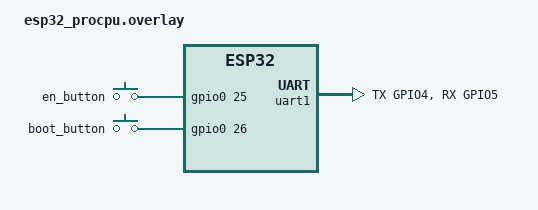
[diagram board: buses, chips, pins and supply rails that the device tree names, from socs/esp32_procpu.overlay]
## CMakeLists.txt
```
# SPDX-License-Identifier: Apache-2.0

cmake_minimum_required(VERSION 3.20.0)

find_package(Zephyr REQUIRED HINTS $ENV{ZEPHYR_BASE})
project(zephyr_flasher)

zephyr_compile_definitions_ifdef(CONFIG_SERIAL_FLASHER_MD5_ENABLED MD5_ENABLED)

zephyr_library_sources(
  ../common/example_common.c
  )

zephyr_library_include_directories(
  ../common
  )

# Needed for example_common
add_compile_definitions(SERIAL_FLASHER_INTERFACE_UART)

# Convert binary files to C source files using bin2array.cmake
include(${CMAKE_SOURCE_DIR}/../common/bin2array.cmake)
create_resources(${CMAKE_SOURCE_DIR}/target-firmware ${CMAKE_BINARY_DIR}/target_firmware_data.c)
set_property(SOURCE ${CMAKE_BINARY_DIR}/target_firmware_data.c PROPERTY GENERATED 1)

target_sources(app PRIVATE
    src/main.c
    ${CMAKE_BINARY_DIR}/target_firmware_data.c
)
```

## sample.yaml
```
sample:
  description: ESP Serial Flasher sample code
  name: zephyr_flasher
tests:
  sample.esp_flasher.zephyr_example:
    platform_allow:
      - esp32_devkitc_wroom
      - esp32_devkitc_wrover
    tags: esp32
```

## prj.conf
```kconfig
# nothing here
CONFIG_CONSOLE=y
CONFIG_CONSOLE_GETCHAR=y
CONFIG_NEWLIB_LIBC=y
```

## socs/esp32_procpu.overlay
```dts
/*
 * Copyright (c) 2024 Espressif Systems (Shanghai) Co., Ltd.
 *
 * SPDX-License-Identifier: Apache-2.0
 */

/ {
	aliases {
		en = &en_button;
		boot = &boot_button;
		uart = &uart1;
	};

	gpio_keys {
		compatible = "gpio-keys";
		en_button: en_button {
			gpios = <&gpio0 25 (GPIO_PULL_UP | GPIO_ACTIVE_HIGH)>;
		};
		boot_button: boot_button {
			gpios = <&gpio0 26 (GPIO_PULL_UP | GPIO_ACTIVE_HIGH)>;
		};
	};
};

&pinctrl {
	uart1_example: uart1_example {
		group1 {
			pinmux = <UART1_TX_GPIO4>;
			input-enable;
		};
		group2 {
			pinmux = <UART1_RX_GPIO5>;
			output-enable;
		};
	};
};

&uart1 {
	status = "okay";
	pinctrl-0 = <&uart1_example>;
	pinctrl-names = "default";
};
```

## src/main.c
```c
/*
 * ESP Flasher Library Example for Zephyr
 * Written in 2022 by KT-Elektronik, Klaucke und Partner GmbH
 * This example code is in the Public Domain (or CC0 licensed, at your option.)
 * Unless required by applicable law or agreed to in writing, this
 * software is distributed on an "AS IS" BASIS, WITHOUT WARRANTIES OR
 * CONDITIONS OF ANY KIND, either express or implied.
 *
 * Copyright (c) 2023 Espressif Systems (Shanghai) Co., Ltd.
 */

#include <zephyr/kernel.h>
#include <zephyr/device.h>
#include <zephyr/devicetree.h>
#include <zephyr/drivers/gpio.h>
#include <zephyr/drivers/uart.h>
#include <zephyr/sys/util.h>

#include <stdio.h>
#include <string.h>
#include <zephyr_port.h>
#include <esp_loader.h>
#include "example_common.h"

// Embedded binary files using bin2array.cmake
extern const uint8_t bootloader_bin[];
extern const uint32_t bootloader_bin_size;
extern const uint8_t bootloader_bin_md5[];
extern const uint8_t partition_table_bin[];
extern const uint32_t partition_table_bin_size;
extern const uint8_t partition_table_bin_md5[];
extern const uint8_t app_bin[];
extern const uint32_t app_bin_size;
extern const uint8_t app_bin_md5[];

#define HIGHER_BAUDRATE 230400
#define DEFAULT_BAUDRATE 115200

/* Get UART DTS entry used as flash interface */
static const struct device *esp_uart_dev = DEVICE_DT_GET(DT_ALIAS(uart));
/* Get GPIO pin connected to the ESP's enable pin. */
static const struct gpio_dt_spec esp_enable_spec = GPIO_DT_SPEC_GET(DT_ALIAS(en), gpios);
/* Get GPIO pin  connected to the ESP's boot pin. */
static const struct gpio_dt_spec esp_boot_spec = GPIO_DT_SPEC_GET(DT_ALIAS(boot), gpios);

int main(void)
{

    const loader_zephyr_config_t config = {
        .uart_dev = esp_uart_dev,
        .enable_spec = esp_enable_spec,
        .boot_spec = esp_boot_spec
    };

    printk("Running ESP Flasher from Zephyr\r\n");

    if (!device_is_ready(esp_uart_dev)) {
        printk("ESP UART not ready");
        return -ENODEV;
    }

    if (!device_is_ready(esp_boot_spec.port)) {
        printk("ESP boot GPIO not ready");
        return -ENODEV;
    }

    if (!device_is_ready(esp_enable_spec.port)) {
        printk("ESP enable GPIO not ready");
        return -ENODEV;
    }

    gpio_pin_configure_dt(&esp_boot_spec, GPIO_OUTPUT_ACTIVE);
    gpio_pin_configure_dt(&esp_enable_spec, GPIO_OUTPUT_INACTIVE);

    if (loader_port_zephyr_init(&config) != ESP_LOADER_SUCCESS) {
        printk("ESP loader init failed");
        return -EIO;
    }

    if (connect_to_target(HIGHER_BAUDRATE) == ESP_LOADER_SUCCESS) {
        printk("Loading bootloader...\n");
        target_chip_t chip = esp_loader_get_target();
        uint32_t bootloader_addr = get_bootloader_address(chip);
        flash_binary(bootloader_bin, bootloader_bin_size, bootloader_addr);
        printk("Loading partition table...\n");
        flash_binary(partition_table_bin, partition_table_bin_size, PARTITION_TABLE_ADDRESS);
        printk("Loading app...\n");
        flash_binary(app_bin, app_bin_size, APPLICATION_ADDRESS);
    }

    esp_loader_reset_target();

    if (loader_port_change_transmission_rate(DEFAULT_BAUDRATE) == ESP_LOADER_SUCCESS) {
        // Delay for skipping the boot message of the targets
        k_msleep(500);

        printk("********************************************\n");
        printk("*** Logs below are print from slave .... ***\n");
        printk("********************************************\n");
        while (1) {
            uint8_t c;
            if (uart_poll_in(esp_uart_dev, &c) == 0) {
                printk("%c", c);
            }
        }
    }
    return 0;
}
```
